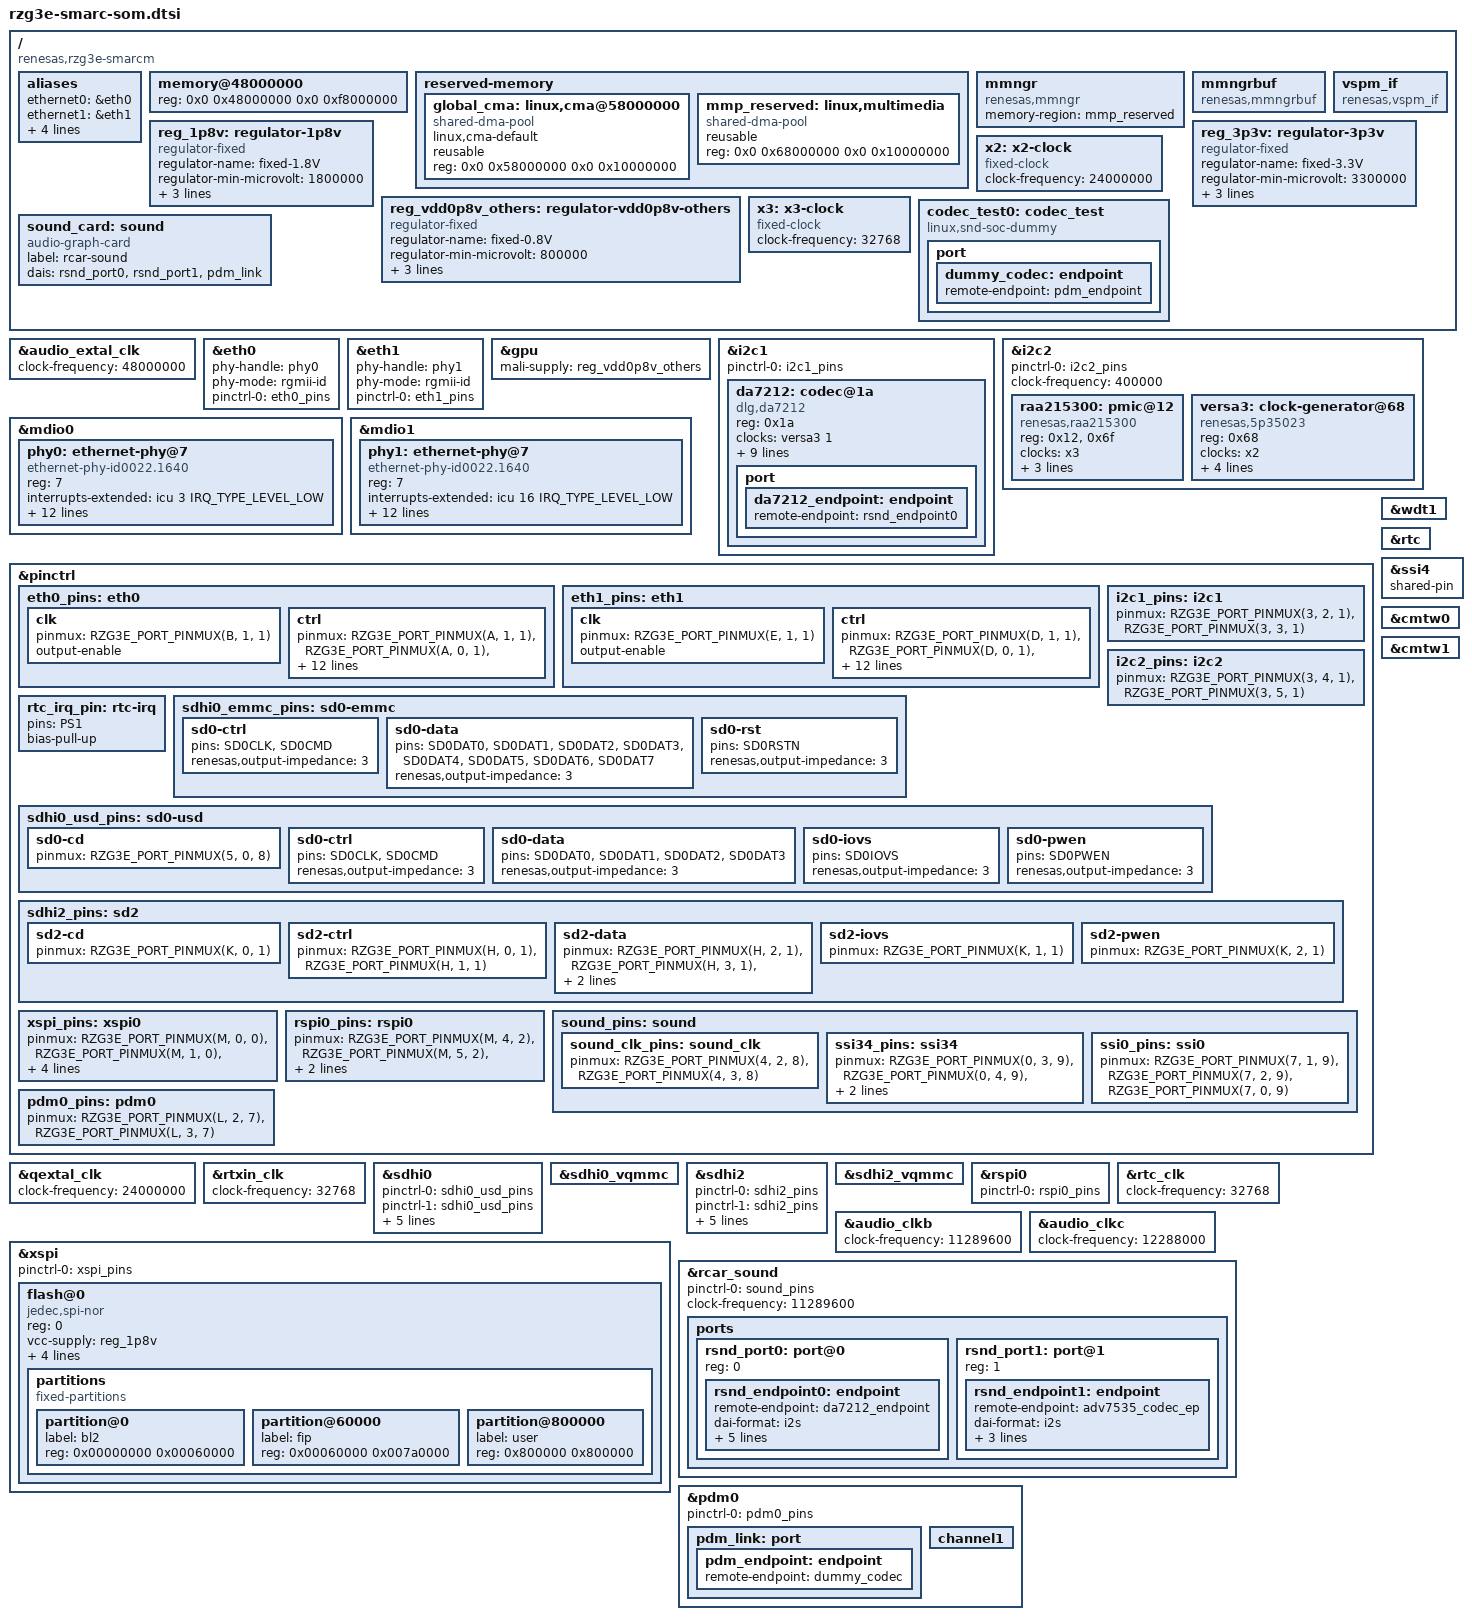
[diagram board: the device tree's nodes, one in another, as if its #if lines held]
// SPDX-License-Identifier: (GPL-2.0-only OR BSD-2-Clause)
/*
 * Device Tree Source for the R9A09G047E57 SMARC SoM board.
 *
 * Copyright (C) 2024 Renesas Electronics Corp.
 */

/*
 * Please set the below switch position on the SoM and the corresponding macro
 * on the board DTS:
 *
 * Switch position SYS.1, Macro SW_SD0_DEV_SEL:
 *      0 - SD0 is connected to eMMC (default)
 *      1 - SD0 is connected to uSD0 card
 *
 * Switch position SYS.5, Macro SW_LCD_EN:
 *      0 - Select Misc. Signals routing
 *      1 - Select LCD
 *
 * Switch position BOOT.6, Macro SW_PDM_EN:
 *      0 - Select CAN routing
 *      1 - Select PDM
 */

/*
 * SSI-DA7212
 *
 * These commands are required when Playback/Capture
 *
 *	amixer -q cset name='Aux Switch' on
 *	amixer -q cset name='Mixin Left Aux Left Switch' on
 *	amixer -q cset name='Mixin Right Aux Right Switch' on
 *	amixer -q cset name='ADC Switch' on
 *	amixer -q cset name='Mixout Right Mixin Right Switch' off
 *	amixer -q cset name='Mixout Left Mixin Left Switch' off
 *	amixer -q cset name='Headphone Volume' 80%
 *	amixer -q cset name='Headphone Switch' on
 *	amixer -q cset name='Mixout Left DAC Left Switch' on
 *	amixer -q cset name='Mixout Right DAC Right Switch' on
 *	amixer -q cset name='DAC Left Source MUX' 'DAI Input Left'
 *	amixer -q cset name='DAC Right Source MUX' 'DAI Input Right'
 *	amixer -q sset 'Mic 1 Amp Source MUX' 'MIC_P'
 *	amixer -q sset 'Mic 2 Amp Source MUX' 'MIC_P'
 *	amixer -q sset 'Mixin Left Mic 1' on
 *	amixer -q sset 'Mixin Right Mic 2' on
 *	amixer -q sset 'Mic 1' 80% on
 *	amixer -q sset 'Mic 2' 80% on
 *	amixer -q sset 'Lineout' 80% on
 *	amixer -q sset 'Mixin PGA' 40% on
 *
 * When Capture, use this command to amplify sound
 *	amixer set 'DVC In',0 10%
 *	amixer set 'DVC Out',0 20%
 */

/ {
	compatible = "renesas,rzg3e-smarcm", "renesas,r9a09g047e57", "renesas,r9a09g047";

	aliases {
		ethernet0 = &eth0;
		ethernet1 = &eth1;
		i2c1 = &i2c1;
		i2c2 = &i2c2;
		mmc0 = &sdhi0;
		mmc2 = &sdhi2;
	};

	memory@48000000 {
		device_type = "memory";
		/* First 128MB is reserved for secure area. */
		reg = <0x0 0x48000000 0x0 0xf8000000>;
	};

	reserved-memory {
		#address-cells = <2>;
		#size-cells = <2>;
		ranges;

		global_cma: linux,cma@58000000 {
			compatible = "shared-dma-pool";
			linux,cma-default;
			reusable;
			reg = <0x0 0x58000000 0x0 0x10000000>;
		};

		mmp_reserved: linux,multimedia {
			compatible = "shared-dma-pool";
			reusable;
			reg = <0x0 0x68000000 0x0 0x10000000>;
		};
	};

	mmngr {
		compatible = "renesas,mmngr";
		memory-region = <&mmp_reserved>;
	};

	mmngrbuf {
		compatible = "renesas,mmngrbuf";
	};

	vspm_if {
		compatible = "renesas,vspm_if";
	};

	reg_1p8v: regulator-1p8v {
		compatible = "regulator-fixed";
		regulator-name = "fixed-1.8V";
		regulator-min-microvolt = <1800000>;
		regulator-max-microvolt = <1800000>;
		regulator-boot-on;
		regulator-always-on;
	};

	reg_3p3v: regulator-3p3v {
		compatible = "regulator-fixed";
		regulator-name = "fixed-3.3V";
		regulator-min-microvolt = <3300000>;
		regulator-max-microvolt = <3300000>;
		regulator-boot-on;
		regulator-always-on;
	};

	reg_vdd0p8v_others: regulator-vdd0p8v-others {
		compatible = "regulator-fixed";

		regulator-name = "fixed-0.8V";
		regulator-min-microvolt = <800000>;
		regulator-max-microvolt = <800000>;
		regulator-boot-on;
		regulator-always-on;
	};

	x2: x2-clock {
		compatible = "fixed-clock";
		#clock-cells = <0>;
		clock-frequency = <24000000>;
	};

	/* 32.768kHz crystal */
	x3: x3-clock {
		compatible = "fixed-clock";
		#clock-cells = <0>;
		clock-frequency = <32768>;
	};

#if (SW_PDM_EN)
	codec_test0: codec_test {
		compatible = "linux,snd-soc-dummy";
		#sound-dai-cells = <0>;
		port {
			dummy_codec: endpoint {
				remote-endpoint = <&pdm_endpoint>;
			};
		};
	};
#endif

	sound_card: sound {
		compatible = "audio-graph-card";

		label = "rcar-sound";
		dais = <&rsnd_port0	/* DA7211 */
			&rsnd_port1	/* HDMI0  */
#if (SW_PDM_EN)
			&pdm_link
#endif
			>;
	};


};

&audio_extal_clk {
	clock-frequency = <48000000>;
};

&eth0 {
	phy-handle = <&phy0>;
	phy-mode = "rgmii-id";

	pinctrl-0 = <&eth0_pins>;
	pinctrl-names = "default";
	status = "okay";
};

&eth1 {
	phy-handle = <&phy1>;
	phy-mode = "rgmii-id";

	pinctrl-0 = <&eth1_pins>;
	pinctrl-names = "default";
	status = "okay";
};

&gpu {
	status = "okay";
	mali-supply = <&reg_vdd0p8v_others>;
};

&i2c1 {
	pinctrl-0 = <&i2c1_pins>;
	pinctrl-names = "default";

	status = "okay";

	da7212: codec@1a {
		compatible = "dlg,da7212";
		#sound-dai-cells = <0>;
		#address-cells = <1>;
		#size-cells = <0>;
		reg = <0x1a>;

		clocks = <&versa3 1>;
		clock-names = "mclk";

		dlg,micbias1-lvl = <2500>;
		dlg,micbias2-lvl = <2500>;
		dlg,dmic-data-sel = "lrise_rfall";
		dlg,dmic-samplephase = "between_clkedge";
		dlg,dmic-clkrate = <3000000>;

		VDDA-supply = <&reg_1p8v>;
		VDDSP-supply = <&reg_3p3v>;
		VDDMIC-supply = <&reg_3p3v>;
		VDDIO-supply = <&reg_1p8v>;

		port {
			da7212_endpoint: endpoint {
				remote-endpoint = <&rsnd_endpoint0>;
			};
		};
	};
};

&i2c2 {
	pinctrl-0 = <&i2c2_pins>;
	pinctrl-names = "default";
	clock-frequency = <400000>;
	status = "okay";

	raa215300: pmic@12 {
		compatible = "renesas,raa215300";
		reg = <0x12>, <0x6f>;
		reg-names = "main", "rtc";
		clocks = <&x3>;
		clock-names = "xin";

		pinctrl-0 = <&rtc_irq_pin>;
		pinctrl-names = "default";

		interrupts-extended = <&pinctrl RZG3E_GPIO(S, 1) IRQ_TYPE_EDGE_FALLING>;
	};

	versa3: clock-generator@68 {
		compatible = "renesas,5p35023";
		reg = <0x68>;
		#clock-cells = <1>;
		clocks = <&x2>;

		assigned-clocks = <&versa3 0>, <&versa3 1>,
				  <&versa3 2>, <&versa3 3>,
				  <&versa3 4>, <&versa3 5>;
		assigned-clock-rates = <24000000>, <12288000>,
				       <11289600>, <12288000>,
				       <25000000>, <25000000>;
	};

};

&mdio0 {
	phy0: ethernet-phy@7 {
		compatible = "ethernet-phy-id0022.1640",
			     "ethernet-phy-ieee802.3-c22";
		reg = <7>;
		interrupts-extended = <&icu 3 IRQ_TYPE_LEVEL_LOW>;
		rxc-skew-psec = <1400>;
		txc-skew-psec = <1400>;
		rxdv-skew-psec = <0>;
		txdv-skew-psec = <0>;
		rxd0-skew-psec = <0>;
		rxd1-skew-psec = <0>;
		rxd2-skew-psec = <0>;
		rxd3-skew-psec = <0>;
		txd0-skew-psec = <0>;
		txd1-skew-psec = <0>;
		txd2-skew-psec = <0>;
		txd3-skew-psec = <0>;
	};
};

&mdio1 {
	phy1: ethernet-phy@7 {
		compatible = "ethernet-phy-id0022.1640",
			     "ethernet-phy-ieee802.3-c22";
		reg = <7>;
		interrupts-extended = <&icu 16 IRQ_TYPE_LEVEL_LOW>;
		rxc-skew-psec = <1400>;
		txc-skew-psec = <1400>;
		rxdv-skew-psec = <0>;
		txdv-skew-psec = <0>;
		rxd0-skew-psec = <0>;
		rxd1-skew-psec = <0>;
		rxd2-skew-psec = <0>;
		rxd3-skew-psec = <0>;
		txd0-skew-psec = <0>;
		txd1-skew-psec = <0>;
		txd2-skew-psec = <0>;
		txd3-skew-psec = <0>;
	};
};

&pinctrl {
	eth0_pins: eth0 {
		clk {
			pinmux = <RZG3E_PORT_PINMUX(B, 1, 1)>; /* TXC */
			output-enable;
		};

		ctrl {
			pinmux = <RZG3E_PORT_PINMUX(A, 1, 1)>, /* MDC */
				 <RZG3E_PORT_PINMUX(A, 0, 1)>, /* MDIO */
				 <RZG3E_PORT_PINMUX(C, 2, 15)>, /* PHY_INTR (IRQ2) */
				 <RZG3E_PORT_PINMUX(C, 1, 1)>, /* RXD3 */
				 <RZG3E_PORT_PINMUX(C, 0, 1)>, /* RXD2 */
				 <RZG3E_PORT_PINMUX(B, 7, 1)>, /* RXD1 */
				 <RZG3E_PORT_PINMUX(B, 6, 1)>, /* RXD0 */
				 <RZG3E_PORT_PINMUX(B, 0, 1)>, /* RXC */
				 <RZG3E_PORT_PINMUX(A, 2, 1)>, /* RX_CTL */
				 <RZG3E_PORT_PINMUX(B, 5, 1)>, /* TXD3 */
				 <RZG3E_PORT_PINMUX(B, 4, 1)>, /* TXD2 */
				 <RZG3E_PORT_PINMUX(B, 3, 1)>, /* TXD1 */
				 <RZG3E_PORT_PINMUX(B, 2, 1)>, /* TXD0 */
				 <RZG3E_PORT_PINMUX(A, 3, 1)>; /* TX_CTL */
		};
	};

	eth1_pins: eth1 {
		clk {
			pinmux = <RZG3E_PORT_PINMUX(E, 1, 1)>; /* TXC */
			output-enable;
		};

		ctrl {

			pinmux = <RZG3E_PORT_PINMUX(D, 1, 1)>, /* MDC */
				 <RZG3E_PORT_PINMUX(D, 0, 1)>, /* MDIO */
				 <RZG3E_PORT_PINMUX(F, 2, 15)>, /* PHY_INTR (IRQ15) */
				 <RZG3E_PORT_PINMUX(F, 1, 1)>, /* RXD3 */
				 <RZG3E_PORT_PINMUX(F, 0, 1)>, /* RXD2 */
				 <RZG3E_PORT_PINMUX(E, 7, 1)>, /* RXD1 */
				 <RZG3E_PORT_PINMUX(E, 6, 1)>, /* RXD0 */
				 <RZG3E_PORT_PINMUX(E, 0, 1)>, /* RXC */
				 <RZG3E_PORT_PINMUX(D, 2, 1)>, /* RX_CTL */
				 <RZG3E_PORT_PINMUX(E, 5, 1)>, /* TXD3 */
				 <RZG3E_PORT_PINMUX(E, 4, 1)>, /* TXD2 */
				 <RZG3E_PORT_PINMUX(E, 3, 1)>, /* TXD1 */
				 <RZG3E_PORT_PINMUX(E, 2, 1)>, /* TXD0 */
				 <RZG3E_PORT_PINMUX(D, 3, 1)>; /* TX_CTL */
		};
	};

	i2c1_pins: i2c1 {
		pinmux = <RZG3E_PORT_PINMUX(3, 2, 1)>, /* SCL1 */
			 <RZG3E_PORT_PINMUX(3, 3, 1)>; /* SDA1 */
	};

	i2c2_pins: i2c2 {
		pinmux = <RZG3E_PORT_PINMUX(3, 4, 1)>, /* SCL2 */
			 <RZG3E_PORT_PINMUX(3, 5, 1)>; /* SDA2 */
	};

	rtc_irq_pin: rtc-irq {
		pins = "PS1";
		bias-pull-up;
	};

	sdhi0_emmc_pins: sd0-emmc {
		sd0-ctrl {
			pins = "SD0CLK", "SD0CMD";
			renesas,output-impedance = <3>;
		};

		sd0-data {
			pins = "SD0DAT0", "SD0DAT1", "SD0DAT2", "SD0DAT3",
			       "SD0DAT4", "SD0DAT5", "SD0DAT6", "SD0DAT7";
			renesas,output-impedance = <3>;
		};

		sd0-rst {
			pins = "SD0RSTN";
			renesas,output-impedance = <3>;
		};
	};

	sdhi0_usd_pins: sd0-usd {
		sd0-cd {
			pinmux = <RZG3E_PORT_PINMUX(5, 0, 8)>;
		};

		sd0-ctrl {
			pins = "SD0CLK", "SD0CMD";
			renesas,output-impedance = <3>;
		};

		sd0-data {
			pins = "SD0DAT0", "SD0DAT1", "SD0DAT2", "SD0DAT3";
			renesas,output-impedance = <3>;
		};

		sd0-iovs {
			pins = "SD0IOVS";
			renesas,output-impedance = <3>;
		};

		sd0-pwen {
			pins = "SD0PWEN";
			renesas,output-impedance = <3>;
		};
	};

	sdhi2_pins: sd2 {
		sd2-cd {
			pinmux = <RZG3E_PORT_PINMUX(K, 0, 1)>; /* SD2CD */
		};

		sd2-ctrl {
			pinmux = <RZG3E_PORT_PINMUX(H, 0, 1)>, /* SD2CLK */
				 <RZG3E_PORT_PINMUX(H, 1, 1)>; /* SD2CMD */
		};

		sd2-data {
			pinmux = <RZG3E_PORT_PINMUX(H, 2, 1)>, /* SD2DAT0 */
				 <RZG3E_PORT_PINMUX(H, 3, 1)>, /* SD2DAT1 */
				 <RZG3E_PORT_PINMUX(H, 4, 1)>, /* SD2DAT2 */
				 <RZG3E_PORT_PINMUX(H, 5, 1)>; /* SD2DAT3 */
		};

		sd2-iovs {
			pinmux = <RZG3E_PORT_PINMUX(K, 1, 1)>; /* SD2IOVS */
		};

		sd2-pwen {
			pinmux = <RZG3E_PORT_PINMUX(K, 2, 1)>; /* SD2PWEN */
		};
	};

	xspi_pins: xspi0 {
		pinmux = <RZG3E_PORT_PINMUX(M, 0, 0)>, /* XSPI0_IO0 */
			 <RZG3E_PORT_PINMUX(M, 1, 0)>, /* XSPI0_IO1 */
			 <RZG3E_PORT_PINMUX(M, 2, 0)>, /* XSPI0_IO2 */
			 <RZG3E_PORT_PINMUX(M, 3, 0)>, /* XSPI0_IO3 */
			 <RZG3E_PORT_PINMUX(L, 0, 0)>, /* XSPI0_CKP */
			 <RZG3E_PORT_PINMUX(L, 1, 0)>; /* XSPI0_CS0 */
	};

	rspi0_pins: rspi0 {
		pinmux = <RZG3E_PORT_PINMUX(M, 4, 2)>, /* MISOA */
			 <RZG3E_PORT_PINMUX(M, 5, 2)>, /* MOSIA */
			 <RZG3E_PORT_PINMUX(M, 7, 2)>, /* SSLA0 */
			 <RZG3E_PORT_PINMUX(M, 6, 2)>; /* RSPCKA */
	};

	sound_pins: sound {
		sound_clk_pins: sound_clk {
			pinmux = <RZG3E_PORT_PINMUX(4, 2, 8)>, /* AUDIO_CLKB */
				 <RZG3E_PORT_PINMUX(4, 3, 8)>; /* AUDIO_CLKC */
		};

		ssi34_pins: ssi34 {
			pinmux = <RZG3E_PORT_PINMUX(0, 3, 9)>, /* SSI3_SCK */
				 <RZG3E_PORT_PINMUX(0, 4, 9)>, /* SSI3_WS */
				 <RZG3E_PORT_PINMUX(0, 2, 9)>, /* SSI3_SDATA */
				 <RZG3E_PORT_PINMUX(0, 5, 9)>; /* SSI4_SDATA */
		};

		ssi0_pins: ssi0 {
			pinmux = <RZG3E_PORT_PINMUX(7, 1, 9)>, /* SSI0_SCK */
				 <RZG3E_PORT_PINMUX(7, 2, 9)>, /* SSI0_WS */
				 <RZG3E_PORT_PINMUX(7, 0, 9)>; /* SSI0_SDATA */
		};
	};
#if (SW_PDM_EN)
	pdm0_pins: pdm0 {
		pinmux = <RZG3E_PORT_PINMUX(L, 2, 7)>, /* PDMCLK01 */
			 <RZG3E_PORT_PINMUX(L, 3, 7)>; /* PDMDAT01 */
	};

#endif

};

&qextal_clk {
	clock-frequency = <24000000>;
};

&rtxin_clk {
	clock-frequency = <32768>;
};

#if (SW_SD0_DEV_SEL)
&sdhi0 {
	pinctrl-0 = <&sdhi0_usd_pins>;
	pinctrl-1 = <&sdhi0_usd_pins>;
	pinctrl-names = "default", "state_uhs";

	vmmc-supply = <&reg_3p3v>;
	vqmmc-supply = <&sdhi0_vqmmc>;
	bus-width = <4>;
	sd-uhs-sdr50;
	sd-uhs-sdr104;
	status = "okay";
};

&sdhi0_vqmmc {
	status = "okay";
};
#else
&sdhi0 {
	pinctrl-0 = <&sdhi0_emmc_pins>;
	pinctrl-1 = <&sdhi0_emmc_pins>;
	pinctrl-names = "default", "state_uhs";

	vmmc-supply = <&reg_3p3v>;
	vqmmc-supply = <&reg_1p8v>;
	bus-width = <8>;
	mmc-hs200-1_8v;
	non-removable;
	fixed-emmc-driver-type = <1>;
	status = "okay";
};
#endif

&sdhi2 {
	pinctrl-0 = <&sdhi2_pins>;
	pinctrl-1 = <&sdhi2_pins>;
	pinctrl-names = "default", "state_uhs";

	vmmc-supply = <&reg_3p3v>;
	vqmmc-supply = <&sdhi2_vqmmc>;
	bus-width = <4>;
	sd-uhs-sdr50;
	sd-uhs-sdr104;
	status = "okay";
};

&sdhi2_vqmmc {
	status = "okay";
};

&wdt1 {
	status = "okay";
};

&rspi0 {
	pinctrl-0 = <&rspi0_pins>;
	pinctrl-names = "default";

	status = "okay";
};

&xspi {
	pinctrl-0 = <&xspi_pins>;
	pinctrl-names = "default";
	status = "okay";

	flash@0 {
		compatible = "jedec,spi-nor";
		reg = <0>;
		vcc-supply = <&reg_1p8v>;
		m25p,fast-read;
		spi-max-frequency = <50000000>;
		spi-tx-bus-width = <4>;
		spi-rx-bus-width = <4>;

		partitions {
			compatible = "fixed-partitions";
			#address-cells = <1>;
			#size-cells = <1>;

			partition@0 {
				label = "bl2";
				reg = <0x00000000 0x00060000>;
			};

			partition@60000 {
				label = "fip";
				reg = <0x00060000 0x007a0000>;
			};

			partition@800000 {
				label = "user";
				reg = <0x800000 0x800000>;
			};
		};
	};
};

&rtc_clk {
	clock-frequency = <32768>;
};

&rtc {
	status = "okay";
};

&audio_extal_clk {
	clock-frequency = <48000000>;
};

&audio_clkb {
	clock-frequency = <11289600>;
};

&audio_clkc {
	clock-frequency = <12288000>;
};

&rcar_sound {
	pinctrl-0 = <&sound_pins>;
	pinctrl-names = "default";

	status = "okay";

	/* audio_clkout */
	#clock-cells = <0>;
	clock-frequency = <11289600>;

	/* Multi DAI */
	#sound-dai-cells = <1>;

	ports {
		#address-cells = <1>;
		#size-cells = <0>;

		rsnd_port0: port@0 {
			reg = <0>;
			rsnd_endpoint0: endpoint {
				remote-endpoint = <&da7212_endpoint>;

				dai-format = "i2s";
				bitclock-master = <&rsnd_endpoint0>;
				frame-master = <&rsnd_endpoint0>;
				mclk-fs = <512>;

				playback = <&ssi3>, <&src0>, <&dvc0>;
				capture = <&ssi4>, <&src1>, <&dvc1>;
			};
		};

#if (!SW_LCD_EN)
		rsnd_port1: port@1 {
			reg = <1>;
			rsnd_endpoint1: endpoint {
				remote-endpoint = <&adv7535_codec_ep>;
				dai-format = "i2s";
				bitclock-master = <&rsnd_endpoint1>;
				frame-master = <&rsnd_endpoint1>;

				playback = <&ssi0>;
			};
		};
#endif
	};
};

#if (SW_PDM_EN)
&pdm0 {
	pinctrl-0 = <&pdm0_pins>;
	pinctrl-names = "default";
	status = "okay";

	pdm_link: port {
		pdm_endpoint: endpoint {
			remote-endpoint = <&dummy_codec>;
		};
	};

	channel1 {
		status = "okay";
	};
};
#endif

&ssi4 {
	shared-pin;
};

&cmtw0 {
	status = "okay";
};

&cmtw1 {
	status = "okay";
};
